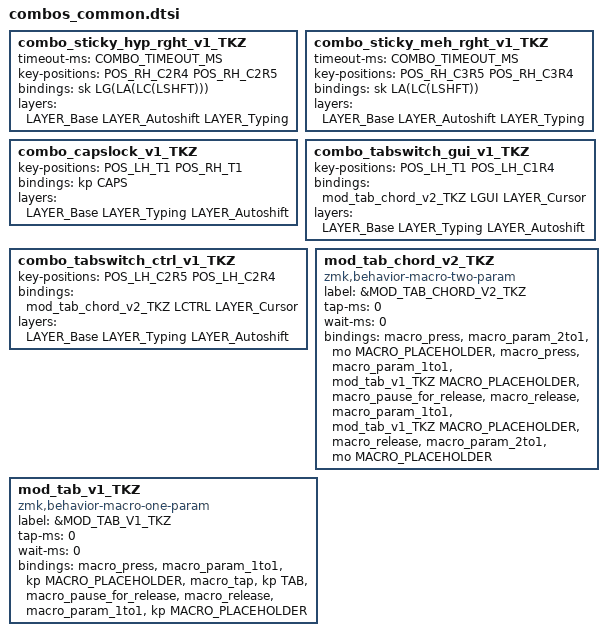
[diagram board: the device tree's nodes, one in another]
// sticky "hyper" modifiers (Win + Alt + Ctrl + Shift) - TailorKey
combo_sticky_hyp_rght_v1_TKZ {
    timeout-ms = <COMBO_TIMEOUT_MS>;
    key-positions = <POS_RH_C2R4 POS_RH_C2R5>;
    bindings = <&sk LG(LA(LC(LSHFT)))>;
    layers = <LAYER_Base LAYER_Autoshift LAYER_Typing>;
};

// sticky "meh" modifiers (Alt + Ctrl + Shift) - TailorKey
combo_sticky_meh_rght_v1_TKZ {
    timeout-ms = <COMBO_TIMEOUT_MS>;
    key-positions = <POS_RH_C3R5 POS_RH_C3R4>;
    bindings = <&sk LA(LC(LSHFT))>;
    layers = <LAYER_Base LAYER_Autoshift LAYER_Typing>;
};

// capslock when pressing both T1's - TailorKey
combo_capslock_v1_TKZ {
    key-positions = <POS_LH_T1 POS_RH_T1>;
    bindings = <&kp CAPS>;
    layers = <LAYER_Base LAYER_Typing LAYER_Autoshift>;
};

// Alt Tab Switcher (Cursor Layer) - TailorKey
combo_tabswitch_gui_v1_TKZ {
    key-positions = <POS_LH_T1 POS_LH_C1R4>;
    bindings = <&mod_tab_chord_v2_TKZ LGUI LAYER_Cursor>;
    layers = <LAYER_Base LAYER_Typing LAYER_Autoshift>;
};

// Ctrl Tab Switcher (Cursor Layer) - TailorKey
combo_tabswitch_ctrl_v1_TKZ {
    key-positions = <POS_LH_C2R5 POS_LH_C2R4>;
    bindings = <&mod_tab_chord_v2_TKZ LCTRL LAYER_Cursor>;
    layers = <LAYER_Base LAYER_Typing LAYER_Autoshift>;
};


// mod_tab_switcher_chord -  TailorKey
mod_tab_chord_v2_TKZ: mod_tab_chord_v2_TKZ {
    label = "&MOD_TAB_CHORD_V2_TKZ";
    compatible = "zmk,behavior-macro-two-param";
    #binding-cells = <2>;
    tap-ms = <0>;
    wait-ms = <0>;
    bindings = <&macro_press>
        , <&macro_param_2to1>
        , <&mo MACRO_PLACEHOLDER>
        , <&macro_press>
        , <&macro_param_1to1>
        , <&mod_tab_v1_TKZ MACRO_PLACEHOLDER>
        , <&macro_pause_for_release>
        , <&macro_release>
        , <&macro_param_1to1>
        , <&mod_tab_v1_TKZ MACRO_PLACEHOLDER>
        , <&macro_release>
        , <&macro_param_2to1>
        , <&mo MACRO_PLACEHOLDER>;
};

// 
// mod_tab_switcher - TailorKey
//
mod_tab_v1_TKZ: mod_tab_v1_TKZ {
    label = "&MOD_TAB_V1_TKZ";
    compatible = "zmk,behavior-macro-one-param";
    #binding-cells = <1>;
    tap-ms = <0>;
    wait-ms = <0>;
    bindings = <&macro_press>
        , <&macro_param_1to1>
        , <&kp MACRO_PLACEHOLDER>
        , <&macro_tap>
        , <&kp TAB>
        , <&macro_pause_for_release>
        , <&macro_release>
        , <&macro_param_1to1>
        , <&kp MACRO_PLACEHOLDER>;
};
